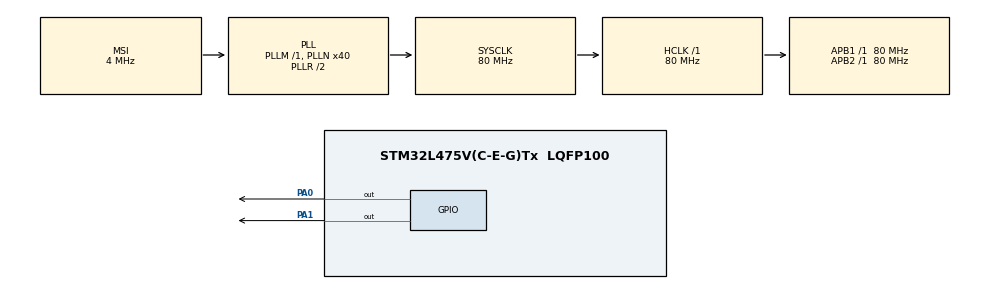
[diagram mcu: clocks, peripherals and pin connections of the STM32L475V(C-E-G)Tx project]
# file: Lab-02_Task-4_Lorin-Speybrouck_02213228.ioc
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Mcu.Family=STM32L4
Mcu.Name=STM32L475V(C-E-G)Tx
Mcu.Package=LQFP100
NVIC.PriorityGroup=NVIC_PRIORITYGROUP_4
PA0.GPIO_Speed=GPIO_SPEED_FREQ_HIGH
PA0.PinState=GPIO_PIN_SET
PA0.Signal=GPIO_Output
PA1.GPIO_ModeDefaultOutputPP=GPIO_MODE_OUTPUT_OD
PA1.GPIO_PuPd=GPIO_PULLUP
PA1.GPIO_Speed=GPIO_SPEED_FREQ_HIGH
PA1.PinState=GPIO_PIN_SET
PA1.Signal=GPIO_Output
ProjectManager.HeapSize=0x200
ProjectManager.StackSize=0x400
ProjectManager.TargetToolchain=STM32CubeIDE
RCC.ADCFreq_Value=48000000
RCC.AHBFreq_Value=80000000
RCC.APB1Freq_Value=80000000
RCC.APB1TimFreq_Value=80000000
RCC.APB2Freq_Value=80000000
RCC.APB2TimFreq_Value=80000000
RCC.CortexFreq_Value=80000000
RCC.HCLKFreq_Value=80000000
RCC.HSE_VALUE=8000000
RCC.HSI_VALUE=16000000
RCC.LSE_VALUE=32768
RCC.MSI_VALUE=4000000
RCC.PLLN=40
RCC.PLLSAI1N=24
RCC.SYSCLKFreq_VALUE=80000000
RCC.SYSCLKSource=RCC_SYSCLKSOURCE_PLLCLK
RCC.USBFreq_Value=48000000
RCC.VCOOutputFreq_Value=160000000
board=B-L475E-IOT01A1

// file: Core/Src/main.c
/* USER CODE BEGIN Header */
/**
 ******************************************************************************
 * @file           : main.c
 * @brief          : Main program body
 ******************************************************************************
 * @attention
 *
 * Copyright (c) 2024 STMicroelectronics.
 * All rights reserved.
 *
 * This software is licensed under terms that can be found in the LICENSE file
 * in the root directory of this software component.
 * If no LICENSE file comes with this software, it is provided AS-IS.
 *
 ******************************************************************************
 */
/* USER CODE END Header */
#include "main.h"

/* USER CODE BEGIN Includes */

#include "fonts.h"
#include "ssd1306.h"

/* USER CODE END Includes */

void SystemClock_Config(void);
static void MX_GPIO_Init(void);

/* USER CODE BEGIN 0 */

//-----------------------------------------------------------------------------
// Low-level software I2C communication to PCB unit on serial LCD display
// pvantorre FEB 2021
//
// Connect Open Smart Rich Shield UART pins top right to LCD unit
// GND----GND
// VCC----VCC
//  TX----SCL (can be remembered as TX is always an output and SCL is always an input)
//  RX----SDA
//-----------------------------------------------------------------------------
//
extern void LCD_Delay(int time); //just a predeclaration

void PCF_SCL(uint8_t level) {
	HAL_GPIO_WritePin(GPIOA, GPIO_PIN_0, level); //TX = SCL
	//HAL_Delay(1);
	LCD_Delay(10);
}

void PCF_SDA(uint8_t level) {
	HAL_GPIO_WritePin(GPIOA, GPIO_PIN_1, level); // RX = SDA
	//HAL_Delay(1);
	LCD_Delay(10);
}

uint8_t PCF_ACK(void) {
	return (HAL_GPIO_ReadPin(GPIOA, GPIO_PIN_1));
}

extern void I2Cstart(void) {
	PCF_SDA(1);
	PCF_SCL(1); //I2C start condition
	PCF_SDA(0); //high to low data while clk high
	PCF_SCL(0);
}

extern void I2Cstop(void) {
	//PCF_SDA(0);
	PCF_SCL(1); //I2C stop condition
	PCF_SDA(1); //low to high data while clk high

}

extern uint8_t I2Cwritebyte(uint8_t databyte)  //MSB first for PCF chip!!!
{
	uint8_t ack;
	for (uint8_t n = 0; n <= 7; n++) {
		if ((databyte & 0x80) > 0)
			PCF_SDA(1);
		else
			PCF_SDA(0);
		PCF_SCL(1);
		databyte <<= 1;
		PCF_SCL(0);
		PCF_SDA(1); //zodat ACK kan gelezen worden
	}
	PCF_SCL(1); //9th clk  ACK
	ack = PCF_ACK();
	PCF_SCL(0);
	return (ack);
}

//-----------------------------------------------------------------------------
// LCD_Delay
//-----------------------------------------------------------------------------
//
void LCD_Delay(int time) {
	int n, m;
	for (n = 0; n < time; n++) {
		//for (m=0;m<20;m++);
	}
}

void draw_circles(int x1, int y1, int x2, int y2, int radius, int delay) {
    float distance = sqrt(pow(x2 - x1, 2) + pow(y2 - y1, 2));
    int num_circles = distance / (2 * radius);

    float step_x = (float)(x2 - x1) / num_circles;
    float step_y = (float)(y2 - y1) / num_circles;

    for (int i = 0; i < num_circles; i++) {
        int x = x1 + i * step_x;
        int y = y1 + i * step_y;
        SSD1306_DrawCircle(x, y, radius, 1);
    	SSD1306_UpdateScreen();
    	HAL_Delay(delay);
    }
}

/* USER CODE END 0 */

int main(void)
{

  /* MCU Configuration--------------------------------------------------------*/

  /* Reset of all peripherals, Initializes the Flash interface and the Systick. */
  HAL_Init();

  /* Configure the system clock */
  SystemClock_Config();

  /* Initialize all configured peripherals */
  MX_GPIO_Init();
  /* USER CODE BEGIN 2 */

	SSD1306_Init();
	SSD1306_Clear();
	draw_circles(5, 3, 126, 64, 3, 10); // LTR diagonal down
	draw_circles(126, 64, 126, 0, 3, 10); // up
	draw_circles(126, 0, 5, 64, 3, 10); // RTL diagonal down
	draw_circles(5, 64, 5, 0, 3, 10); // up

  /* USER CODE END 2 */

  /* Infinite loop */
	while (1) {

	}
}

void SystemClock_Config(void)
{
  RCC_OscInitTypeDef RCC_OscInitStruct = {0};
  RCC_ClkInitTypeDef RCC_ClkInitStruct = {0};

  /** Configure the main internal regulator output voltage
  */
  if (HAL_PWREx_ControlVoltageScaling(PWR_REGULATOR_VOLTAGE_SCALE1) != HAL_OK)
  {
    Error_Handler();
  }

  /** Initializes the RCC Oscillators according to the specified parameters
  * in the RCC_OscInitTypeDef structure.
  */
  RCC_OscInitStruct.OscillatorType = RCC_OSCILLATORTYPE_MSI;
  RCC_OscInitStruct.MSIState = RCC_MSI_ON;
  RCC_OscInitStruct.MSICalibrationValue = 0;
  RCC_OscInitStruct.MSIClockRange = RCC_MSIRANGE_6;
  RCC_OscInitStruct.PLL.PLLState = RCC_PLL_ON;
  RCC_OscInitStruct.PLL.PLLSource = RCC_PLLSOURCE_MSI;
  RCC_OscInitStruct.PLL.PLLM = 1;
  RCC_OscInitStruct.PLL.PLLN = 40;
  RCC_OscInitStruct.PLL.PLLP = RCC_PLLP_DIV7;
  RCC_OscInitStruct.PLL.PLLQ = RCC_PLLQ_DIV2;
  RCC_OscInitStruct.PLL.PLLR = RCC_PLLR_DIV2;
  if (HAL_RCC_OscConfig(&RCC_OscInitStruct) != HAL_OK)
  {
    Error_Handler();
  }

  /** Initializes the CPU, AHB and APB buses clocks
  */
  RCC_ClkInitStruct.ClockType = RCC_CLOCKTYPE_HCLK|RCC_CLOCKTYPE_SYSCLK
                              |RCC_CLOCKTYPE_PCLK1|RCC_CLOCKTYPE_PCLK2;
  RCC_ClkInitStruct.SYSCLKSource = RCC_SYSCLKSOURCE_PLLCLK;
  RCC_ClkInitStruct.AHBCLKDivider = RCC_SYSCLK_DIV1;
  RCC_ClkInitStruct.APB1CLKDivider = RCC_HCLK_DIV1;
  RCC_ClkInitStruct.APB2CLKDivider = RCC_HCLK_DIV1;

  if (HAL_RCC_ClockConfig(&RCC_ClkInitStruct, FLASH_LATENCY_4) != HAL_OK)
  {
    Error_Handler();
  }
}

static void MX_GPIO_Init(void)
{
  GPIO_InitTypeDef GPIO_InitStruct = {0};

  /* GPIO Ports Clock Enable */
  __HAL_RCC_GPIOA_CLK_ENABLE();

  /*Configure GPIO pin Output Level */
  HAL_GPIO_WritePin(GPIOA, GPIO_PIN_0|GPIO_PIN_1, GPIO_PIN_SET);

  /*Configure GPIO pin : PA0 */
  GPIO_InitStruct.Pin = GPIO_PIN_0;
  GPIO_InitStruct.Mode = GPIO_MODE_OUTPUT_PP;
  GPIO_InitStruct.Pull = GPIO_NOPULL;
  GPIO_InitStruct.Speed = GPIO_SPEED_FREQ_HIGH;
  HAL_GPIO_Init(GPIOA, &GPIO_InitStruct);

  /*Configure GPIO pin : PA1 */
  GPIO_InitStruct.Pin = GPIO_PIN_1;
  GPIO_InitStruct.Mode = GPIO_MODE_OUTPUT_OD;
  GPIO_InitStruct.Pull = GPIO_PULLUP;
  GPIO_InitStruct.Speed = GPIO_SPEED_FREQ_HIGH;
  HAL_GPIO_Init(GPIOA, &GPIO_InitStruct);

}

void Error_Handler(void)
{
	__disable_irq();
	while (1) {
	}
}
